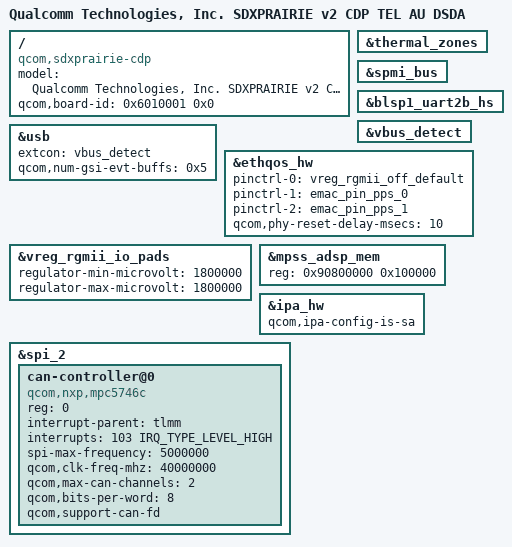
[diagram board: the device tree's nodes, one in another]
// SPDX-License-Identifier: BSD-3-Clause
/*
 * Copyright (c) Qualcomm Technologies, Inc. and/or its subsidiaries.
 */

/dts-v1/;

#include "sa515m-v2.dtsi"
#include "sdx55-cdp.dtsi"

/ {
	model = "Qualcomm Technologies, Inc. SDXPRAIRIE v2 CDP TEL AU DSDA";
	compatible = "qcom,sdxprairie-cdp",
		"qcom,sdxprairie", "qcom,cdp",
		"qcom,sa515m";
	qcom,board-id = <0x6010001 0x0>;
};

/* delete pm8150b nodes */
&thermal_zones {
	/delete-node/ pm8150b-wp-therm;
	/delete-node/ pm8150b_tz;
	/delete-node/ pm8150b-ibat-lvl0;
	/delete-node/ pm8150b-ibat-lvl1;
	/delete-node/ pm8150b-vbat-lvl0;
	/delete-node/ pm8150b-vbat-lvl1;
	/delete-node/ pm8150b-vbat-lvl2;
	/delete-node/ pm8150b-bcl-lvl0;
	/delete-node/ pm8150b-bcl-lvl1;
	/delete-node/ pm8150b-bcl-lvl2;
	/delete-node/ soc;
};

&usb {
	extcon = <&vbus_detect>;
	qcom,num-gsi-evt-buffs = <0x5>;
};

&spmi_bus {
	/delete-node/ qpnp,fg;
	/delete-node/ bcl@1d00;
	/delete-node/ qcom,usb-pdphy@1700;
	/delete-node/ qcom,qpnp-smb5;
	/delete-node/ adc_tm@3500;
	/delete-node/ vadc@3100;
	/delete-node/ qcom,pm8150b@2;
	/delete-node/ qcom,pm8150b@3;
};

&blsp1_uart2b_hs {
	status = "okay";
};

&vbus_detect {
	status = "okay";
};

&ethqos_hw {
	/delete-property/ vreg_rgmii-supply;
	pinctrl-names = "default",
		"dev-emac_pin_pps_0",
		"dev-emac_pin_pps_1";
	pinctrl-0 = <&vreg_rgmii_off_default>;
	pinctrl-1 = <&emac_pin_pps_0>;
	pinctrl-2 = <&emac_pin_pps_1>;
	qcom,phy-reset-delay-msecs = <10>;
};

&vreg_rgmii_io_pads {
	regulator-min-microvolt = <1800000>;
	regulator-max-microvolt = <1800000>;
};

&mpss_adsp_mem {
	/* dual NAND recovery ramdisk image we need to use more ddr ram memory
         during OTA update, so we are reducing this ram usage from
         adsp in recovery kernel image*/
	reg = <0x90800000 0x100000>;
};

&ipa_hw {
	qcom,ipa-config-is-sa;
};

&spi_2 {
	status = "okay";

	can-controller@0 {
		compatible = "qcom,nxp,mpc5746c";
		reg = <0>;
		interrupt-parent = <&tlmm>;
		interrupts = <103 IRQ_TYPE_LEVEL_HIGH>;
		spi-max-frequency = <5000000>;
		qcom,clk-freq-mhz = <40000000>;
		qcom,max-can-channels = <2>;
		qcom,bits-per-word = <8>;
		qcom,support-can-fd;
	};
};
